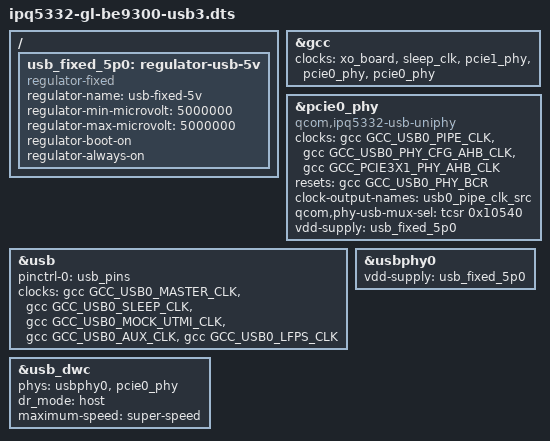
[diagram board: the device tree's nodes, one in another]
// SPDX-License-Identifier: (GPL-2.0+ OR BSD-3-Clause)

/*
 * Keep the base Flint 3 board description intact and override only the
 * USB path.  This makes the USB3 enablement easy to review separately from
 * the already-tested Ethernet, Wi-Fi, eMMC and thermal board definitions.
 */
#include "ipq5332-gl-be9300.dts"

/ {
	usb_fixed_5p0: regulator-usb-5v {
		compatible = "regulator-fixed";
		regulator-name = "usb-fixed-5v";
		regulator-min-microvolt = <5000000>;
		regulator-max-microvolt = <5000000>;
		regulator-boot-on;
		regulator-always-on;
	};
};

/*
 * The fifth GCC parent is the USB/PCIe wrapper PIPE source.  PCIe1 is used
 * by the QCN9274 radio; the otherwise-unused PCIe0 combo block supplies the
 * SuperSpeed USB PHY and its 250 MHz PIPE clock.
 */
&gcc {
	clocks = <&xo_board>,
		 <&sleep_clk>,
		 <&pcie1_phy>,
		 <&pcie0_phy>,
		 <&pcie0_phy>;
};

&pcie0_phy {
	compatible = "qcom,ipq5332-usb-uniphy";

	clocks = <&gcc GCC_USB0_PIPE_CLK>,
		 <&gcc GCC_USB0_PHY_CFG_AHB_CLK>,
		 <&gcc GCC_PCIE3X1_PHY_AHB_CLK>;
	clock-names = "pipe", "phy_cfg_ahb", "phy_ahb";

	resets = <&gcc GCC_USB0_PHY_BCR>;
	reset-names = "por_rst";

	#clock-cells = <0>;
	#phy-cells = <0>;
	clock-output-names = "usb0_pipe_clk_src";

	qcom,phy-usb-mux-sel = <&tcsr 0x10540>;
	vdd-supply = <&usb_fixed_5p0>;

	/delete-property/ num-lanes;
	status = "okay";
};

&usb {
	pinctrl-0 = <&usb_pins>;
	pinctrl-names = "default";

	clocks = <&gcc GCC_USB0_MASTER_CLK>,
		 <&gcc GCC_USB0_SLEEP_CLK>,
		 <&gcc GCC_USB0_MOCK_UTMI_CLK>,
		 <&gcc GCC_USB0_AUX_CLK>,
		 <&gcc GCC_USB0_LFPS_CLK>;
	clock-names = "core",
		      "sleep",
		      "mock_utmi",
		      "aux",
		      "lfps";

	/* This USB2-only PIPE selection prevents external SuperSpeed links. */
	/delete-property/ qcom,select-utmi-as-pipe-clk;
	status = "okay";
};

&usb_dwc {
	/* Remove the superseded properties from the earlier partial attempt. */
	/delete-property/ pinctrl-0;
	/delete-property/ pinctrl-names;
	/delete-property/ qcom,multiplexed-phy;

	phys = <&usbphy0>, <&pcie0_phy>;
	phy-names = "usb2-phy", "usb3-phy";
	dr_mode = "host";
	maximum-speed = "super-speed";
	status = "okay";
};

&usbphy0 {
	vdd-supply = <&usb_fixed_5p0>;
	status = "okay";
};
